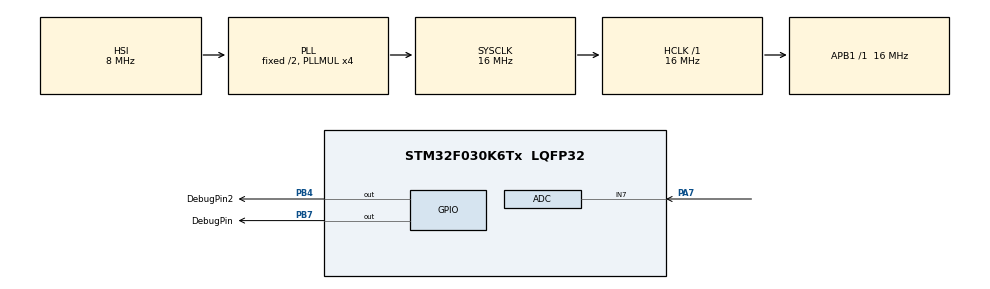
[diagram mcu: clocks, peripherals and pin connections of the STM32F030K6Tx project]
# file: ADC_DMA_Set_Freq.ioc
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ADC.ClockPrescaler=ADC_CLOCK_SYNC_PCLK_DIV2
ADC.ContinuousConvMode=DISABLE
ADC.DMAContinuousRequests=ENABLE
ADC.DiscontinuousConvMode=ENABLE
ADC.ExternalTrigConv=ADC_EXTERNALTRIGCONV_T1_TRGO
ADC.SamplingTime=ADC_SAMPLETIME_1CYCLE_5
Dma.ADC.0.Direction=DMA_PERIPH_TO_MEMORY
Dma.ADC.0.Instance=DMA1_Channel1
Dma.ADC.0.MemDataAlignment=DMA_MDATAALIGN_HALFWORD
Dma.ADC.0.MemInc=DMA_MINC_ENABLE
Dma.ADC.0.Mode=DMA_CIRCULAR
Dma.ADC.0.PeriphDataAlignment=DMA_PDATAALIGN_HALFWORD
Dma.ADC.0.PeriphInc=DMA_PINC_DISABLE
Dma.ADC.0.Priority=DMA_PRIORITY_HIGH
Dma.Request0=ADC
Mcu.Family=STM32F0
Mcu.Name=STM32F030K6Tx
Mcu.Package=LQFP32
NVIC.DMA1_Channel1_IRQn=true\:0\:0\:false\:false\:true\:false\:true
NVIC.TIM1_BRK_UP_TRG_COM_IRQn=true\:0\:0\:false\:false\:true\:true\:true
PA13.Mode=Serial_Wire
PA13.Signal=SYS_SWDIO
PA14.Mode=Serial_Wire
PA14.Signal=SYS_SWCLK
PA7.Mode=IN7
PA7.Signal=ADC_IN7
PB4.GPIO_Label=DebugPin2
PB4.Signal=GPIO_Output
PB7.GPIO_Label=DebugPin
PB7.Signal=GPIO_Output
ProjectManager.HeapSize=0x200
ProjectManager.StackSize=0x400
ProjectManager.TargetToolchain=STM32CubeIDE
RCC.AHBFreq_Value=16000000
RCC.APB1Freq_Value=16000000
RCC.APB1TimFreq_Value=16000000
RCC.HCLKFreq_Value=16000000
RCC.PLLMUL=RCC_PLL_MUL4
RCC.SYSCLKFreq_VALUE=16000000
RCC.SYSCLKSource=RCC_SYSCLKSOURCE_PLLCLK
TIM1.Period=363-1
TIM1.Prescaler=0
TIM1.TIM_MasterOutputTrigger=TIM_TRGO_UPDATE
VP_TIM1_VS_ClockSourceINT.Mode=Internal
board=custom

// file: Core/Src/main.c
/* USER CODE BEGIN Header */
/**
 * Works.
 *
 *
 * Goal background
 * Previously, I've managed to get an ADC clocked on a timer rather than kinda
 * free running, but the code was kinda sloppy with sooo many interrupts.
 *
 * Goal this time
 * Trigger a sequence of n samples, with a DMA callback triggering only at the end
 * of the n samples, not after every sample.
 *
  ******************************************************************************
  * @file           : main.c
  * @brief          : Main program body
  ******************************************************************************
  * @attention
  *
  * Copyright (c) 2022 STMicroelectronics.
  * All rights reserved.
  *
  * This software is licensed under terms that can be found in the LICENSE file
  * in the root directory of this software component.
  * If no LICENSE file comes with this software, it is provided AS-IS.
  *
  ******************************************************************************
  */
/* USER CODE END Header */
#include "main.h"

/* USER CODE BEGIN PD */

#define DMA_BUFFER_LEN 16

/* USER CODE END PD */

ADC_HandleTypeDef hadc;
DMA_HandleTypeDef hdma_adc;

TIM_HandleTypeDef htim1;

/* USER CODE BEGIN PV */
uint16_t DmaBuffer [DMA_BUFFER_LEN];
/* USER CODE END PV */

void SystemClock_Config(void);
static void MX_GPIO_Init(void);
static void MX_DMA_Init(void);
static void MX_ADC_Init(void);
static void MX_TIM1_Init(void);

/* USER CODE BEGIN 0 */

void HAL_TIM_PeriodElapsedCallback(TIM_HandleTypeDef *htim)
{
  /* Prevent unused argument(s) compilation warning */
  UNUSED(htim);

  HAL_GPIO_TogglePin(DebugPin_GPIO_Port, DebugPin_Pin);
}

void HAL_ADC_ConvCpltCallback(ADC_HandleTypeDef* hadc)
{
  /* Prevent unused argument(s) compilation warning */
  UNUSED(hadc);

  HAL_GPIO_TogglePin(DebugPin2_GPIO_Port, DebugPin2_Pin);
}

/* USER CODE END 0 */

int main(void)
{

  /* MCU Configuration--------------------------------------------------------*/

  /* Reset of all peripherals, Initializes the Flash interface and the Systick. */
  HAL_Init();

  /* Configure the system clock */
  SystemClock_Config();

  /* Initialize all configured peripherals */
  MX_GPIO_Init();
  MX_DMA_Init();
  MX_ADC_Init();
  MX_TIM1_Init();

  /* Infinite loop */
  /* USER CODE BEGIN WHILE */

  HAL_TIM_Base_Start_IT(&htim1);
  HAL_ADC_Start_DMA(&hadc, (uint32_t*)DmaBuffer, DMA_BUFFER_LEN);
  while (1)
  {
    /* USER CODE END WHILE */

    /* USER CODE BEGIN 3 */
	  //HAL_GPIO_TogglePin(DebugPin_GPIO_Port, DebugPin_Pin); HAL_Delay(10);
  }
  /* USER CODE END 3 */
}

void SystemClock_Config(void)
{
  RCC_OscInitTypeDef RCC_OscInitStruct = {0};
  RCC_ClkInitTypeDef RCC_ClkInitStruct = {0};

  /** Initializes the RCC Oscillators according to the specified parameters
  * in the RCC_OscInitTypeDef structure.
  */
  RCC_OscInitStruct.OscillatorType = RCC_OSCILLATORTYPE_HSI;
  RCC_OscInitStruct.HSIState = RCC_HSI_ON;
  RCC_OscInitStruct.HSICalibrationValue = RCC_HSICALIBRATION_DEFAULT;
  RCC_OscInitStruct.PLL.PLLState = RCC_PLL_ON;
  RCC_OscInitStruct.PLL.PLLSource = RCC_PLLSOURCE_HSI;
  RCC_OscInitStruct.PLL.PLLMUL = RCC_PLL_MUL4;
  RCC_OscInitStruct.PLL.PREDIV = RCC_PREDIV_DIV1;
  if (HAL_RCC_OscConfig(&RCC_OscInitStruct) != HAL_OK)
  {
    Error_Handler();
  }
  /** Initializes the CPU, AHB and APB buses clocks
  */
  RCC_ClkInitStruct.ClockType = RCC_CLOCKTYPE_HCLK|RCC_CLOCKTYPE_SYSCLK
                              |RCC_CLOCKTYPE_PCLK1;
  RCC_ClkInitStruct.SYSCLKSource = RCC_SYSCLKSOURCE_PLLCLK;
  RCC_ClkInitStruct.AHBCLKDivider = RCC_SYSCLK_DIV1;
  RCC_ClkInitStruct.APB1CLKDivider = RCC_HCLK_DIV1;

  if (HAL_RCC_ClockConfig(&RCC_ClkInitStruct, FLASH_LATENCY_0) != HAL_OK)
  {
    Error_Handler();
  }
}

static void MX_ADC_Init(void)
{

  ADC_ChannelConfTypeDef sConfig = {0};

  /** Configure the global features of the ADC (Clock, Resolution, Data Alignment and number of conversion)
  */
  hadc.Instance = ADC1;
  hadc.Init.ClockPrescaler = ADC_CLOCK_SYNC_PCLK_DIV2;
  hadc.Init.Resolution = ADC_RESOLUTION_12B;
  hadc.Init.DataAlign = ADC_DATAALIGN_RIGHT;
  hadc.Init.ScanConvMode = ADC_SCAN_DIRECTION_FORWARD;
  hadc.Init.EOCSelection = ADC_EOC_SINGLE_CONV;
  hadc.Init.LowPowerAutoWait = DISABLE;
  hadc.Init.LowPowerAutoPowerOff = DISABLE;
  hadc.Init.ContinuousConvMode = DISABLE;
  hadc.Init.DiscontinuousConvMode = ENABLE;
  hadc.Init.ExternalTrigConv = ADC_EXTERNALTRIGCONV_T1_TRGO;
  hadc.Init.ExternalTrigConvEdge = ADC_EXTERNALTRIGCONVEDGE_RISING;
  hadc.Init.DMAContinuousRequests = ENABLE;
  hadc.Init.Overrun = ADC_OVR_DATA_PRESERVED;
  if (HAL_ADC_Init(&hadc) != HAL_OK)
  {
    Error_Handler();
  }
  /** Configure for the selected ADC regular channel to be converted.
  */
  sConfig.Channel = ADC_CHANNEL_7;
  sConfig.Rank = ADC_RANK_CHANNEL_NUMBER;
  sConfig.SamplingTime = ADC_SAMPLETIME_1CYCLE_5;
  if (HAL_ADC_ConfigChannel(&hadc, &sConfig) != HAL_OK)
  {
    Error_Handler();
  }

}

static void MX_TIM1_Init(void)
{

  TIM_ClockConfigTypeDef sClockSourceConfig = {0};
  TIM_MasterConfigTypeDef sMasterConfig = {0};

  htim1.Instance = TIM1;
  htim1.Init.Prescaler = 0;
  htim1.Init.CounterMode = TIM_COUNTERMODE_UP;
  htim1.Init.Period = 363-1;
  htim1.Init.ClockDivision = TIM_CLOCKDIVISION_DIV1;
  htim1.Init.RepetitionCounter = 0;
  htim1.Init.AutoReloadPreload = TIM_AUTORELOAD_PRELOAD_DISABLE;
  if (HAL_TIM_Base_Init(&htim1) != HAL_OK)
  {
    Error_Handler();
  }
  sClockSourceConfig.ClockSource = TIM_CLOCKSOURCE_INTERNAL;
  if (HAL_TIM_ConfigClockSource(&htim1, &sClockSourceConfig) != HAL_OK)
  {
    Error_Handler();
  }
  sMasterConfig.MasterOutputTrigger = TIM_TRGO_UPDATE;
  sMasterConfig.MasterSlaveMode = TIM_MASTERSLAVEMODE_DISABLE;
  if (HAL_TIMEx_MasterConfigSynchronization(&htim1, &sMasterConfig) != HAL_OK)
  {
    Error_Handler();
  }

}

static void MX_DMA_Init(void)
{

  /* DMA controller clock enable */
  __HAL_RCC_DMA1_CLK_ENABLE();

  /* DMA interrupt init */
  /* DMA1_Channel1_IRQn interrupt configuration */
  HAL_NVIC_SetPriority(DMA1_Channel1_IRQn, 0, 0);
  HAL_NVIC_EnableIRQ(DMA1_Channel1_IRQn);

}

static void MX_GPIO_Init(void)
{
  GPIO_InitTypeDef GPIO_InitStruct = {0};

  /* GPIO Ports Clock Enable */
  __HAL_RCC_GPIOA_CLK_ENABLE();
  __HAL_RCC_GPIOB_CLK_ENABLE();

  /*Configure GPIO pin Output Level */
  HAL_GPIO_WritePin(GPIOB, DebugPin2_Pin|DebugPin_Pin, GPIO_PIN_RESET);

  /*Configure GPIO pins : DebugPin2_Pin DebugPin_Pin */
  GPIO_InitStruct.Pin = DebugPin2_Pin|DebugPin_Pin;
  GPIO_InitStruct.Mode = GPIO_MODE_OUTPUT_PP;
  GPIO_InitStruct.Pull = GPIO_NOPULL;
  GPIO_InitStruct.Speed = GPIO_SPEED_FREQ_LOW;
  HAL_GPIO_Init(GPIOB, &GPIO_InitStruct);

}

void Error_Handler(void)
{
  __disable_irq();
  while (1)
  {
  }
}
